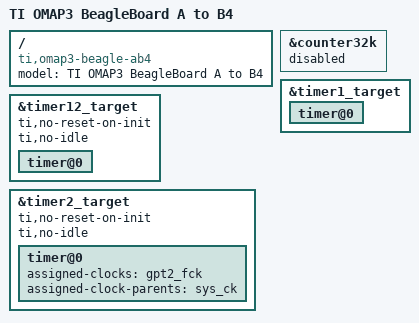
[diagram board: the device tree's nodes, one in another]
/dts-v1/;
#include "omap3-beagle.dts"
/ {
	model = "TI OMAP3 BeagleBoard A to B4";
	compatible = "ti,omap3-beagle-ab4", "ti,omap3-beagle", "ti,omap3430", "ti,omap3";
};
&counter32k {
	status = "disabled";
};
&timer1_target {
	/delete-property/ti,no-reset-on-init;
	/delete-property/ti,no-idle;
	timer@0 {
		/delete-property/ti,timer-alwon;
	};
};
&timer12_target {
	ti,no-reset-on-init;
	ti,no-idle;
	timer@0 {
	};
};
&timer2_target {
	ti,no-reset-on-init;
	ti,no-idle;
	timer@0 {
		assigned-clocks = <&gpt2_fck>;
		assigned-clock-parents = <&sys_ck>;
	};
};
